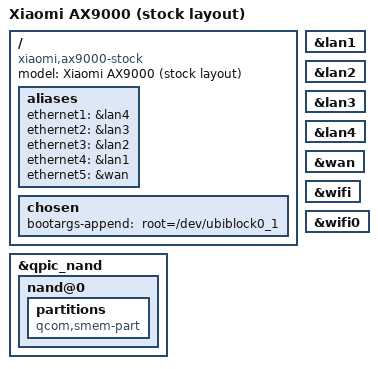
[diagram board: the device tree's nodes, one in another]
// SPDX-License-Identifier: GPL-2.0-or-later OR MIT

#include "ipq8072-ax9000.dts"

/ {
	model = "Xiaomi AX9000 (stock layout)";
	compatible = "xiaomi,ax9000-stock", "qcom,ipq8074";

	aliases {
		/* Aliases as required by u-boot to patch MAC addresses */
		ethernet1 = &lan4;
		ethernet2 = &lan3;
		ethernet3 = &lan2;
		ethernet4 = &lan1;
		ethernet5 = &wan;
	};

	chosen {
		bootargs-append = " root=/dev/ubiblock0_1";
	};
};

&qpic_nand {
	/delete-node/ partitions;

	nand@0 {
		/delete-node/ partitions;

		partitions {
			compatible = "qcom,smem-part";
		};
	};
};

&lan1 {
	/delete-property/ nvmem-cells;
	/delete-property/ nvmem-cell-names;
};

&lan2 {
	/delete-property/ nvmem-cells;
	/delete-property/ nvmem-cell-names;
};

&lan3 {
	/delete-property/ nvmem-cells;
	/delete-property/ nvmem-cell-names;
};

&lan4 {
	/delete-property/ nvmem-cells;
	/delete-property/ nvmem-cell-names;
};

&wan {
	/delete-property/ nvmem-cells;
	/delete-property/ nvmem-cell-names;
};

&wifi {
	/delete-property/ nvmem-cells;
	/delete-property/ nvmem-cell-names;
};

&wifi0 {
	/delete-property/ nvmem-cells;
	/delete-property/ nvmem-cell-names;
};
